# LM3S1626 register map
File version: 7944
Registers are 32-bit, read-write, no defined reset value unless marked. A register's access mark holds for its fields unless they carry their own. Offsets are from the block's base; [hi:lo] are bit positions; {n}, {i} and the like mark numbered series.

## QEI0 — Register map for QEI0 peripheral
Base 0x4002C000; register names take the prefix QEI0
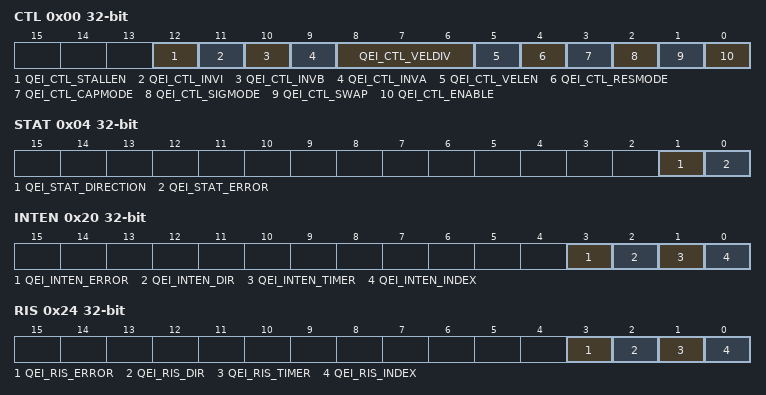
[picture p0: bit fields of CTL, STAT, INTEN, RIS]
0x00 CTL — QEI Control
  [12] QEI_CTL_STALLEN — Stall QEI
  [11] QEI_CTL_INVI — Invert Index Pulse
  [10] QEI_CTL_INVB — Invert PhB
  [9] QEI_CTL_INVA — Invert PhA
  [8:6] QEI_CTL_VELDIV — Predivide Velocity
    0=QEI clock /1; 1=QEI clock /2; 2=QEI clock /4; 3=QEI clock /8; 4=QEI clock /16; 5=QEI clock /32; 6=QEI clock /64; 7=QEI clock /128
  [5] QEI_CTL_VELEN — Capture Velocity
  [4] QEI_CTL_RESMODE — Reset Mode
  [3] QEI_CTL_CAPMODE — Capture Mode
  [2] QEI_CTL_SIGMODE — Signal Mode
  [1] QEI_CTL_SWAP — Swap Signals
  [0] QEI_CTL_ENABLE — Enable QEI
0x04 STAT — QEI Status
  [1] QEI_STAT_DIRECTION — Direction of Rotation
  [0] QEI_STAT_ERROR — Error Detected
0x08 POS — QEI Position
  [31:0] QEI_POS — Current Position Integrator Value
0x0C MAXPOS — QEI Maximum Position
  [31:0] QEI_MAXPOS — Maximum Position Integrator Value
0x10 LOAD — QEI Timer Load
  [31:0] QEI_LOAD — Velocity Timer Load Value
0x14 TIME — QEI Timer
  [31:0] QEI_TIME — Velocity Timer Current Value
0x18 COUNT — QEI Velocity Counter
  [31:0] QEI_COUNT — Velocity Pulse Count
0x1C SPEED — QEI Velocity
  [31:0] QEI_SPEED — Velocity
0x20 INTEN — QEI Interrupt Enable
  [3] QEI_INTEN_ERROR — Phase Error Interrupt Enable
  [2] QEI_INTEN_DIR — Direction Change Interrupt Enable
  [1] QEI_INTEN_TIMER — Timer Expires Interrupt Enable
  [0] QEI_INTEN_INDEX — Index Pulse Detected Interrupt Enable
0x24 RIS — QEI Raw Interrupt Status
  [3] QEI_RIS_ERROR — Phase Error Detected
  [2] QEI_RIS_DIR — Direction Change Detected
  [1] QEI_RIS_TIMER — Velocity Timer Expired
  [0] QEI_RIS_INDEX — Index Pulse Asserted
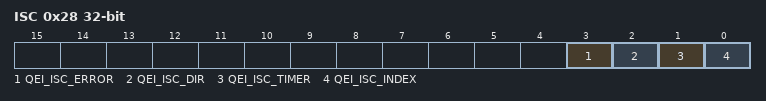
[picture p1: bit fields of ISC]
0x28 ISC — QEI Interrupt Status and Clear
  [3] QEI_ISC_ERROR — Phase Error Interrupt
  [2] QEI_ISC_DIR — Direction Change Interrupt
  [1] QEI_ISC_TIMER — Velocity Timer Expired Interrupt
  [0] QEI_ISC_INDEX — Index Pulse Interrupt

## FLASH_CTRL — Register map for FLASH_CTRL peripheral
Base 0x400FD000; register names take the prefix FLASH_CTRL
0x00 FMA — Flash Memory Address
  [16:0] FLASH_FMA_OFFSET — Address Offset
0x04 FMD — Flash Memory Data
  [31:0] FLASH_FMD_DATA — Data Value
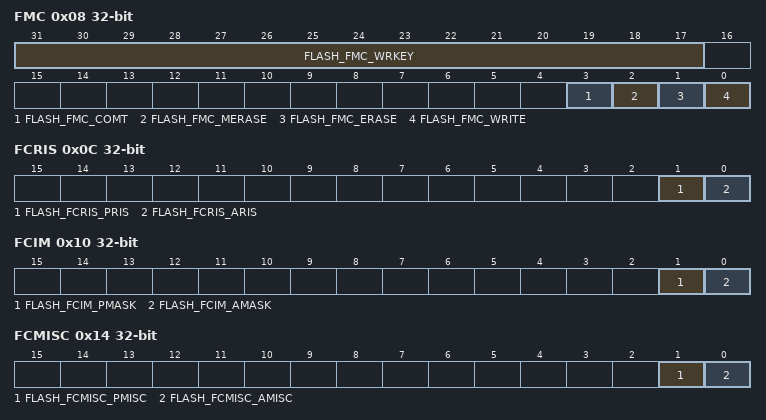
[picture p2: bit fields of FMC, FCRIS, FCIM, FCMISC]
0x08 FMC — Flash Memory Control
  [31:17] FLASH_FMC_WRKEY — FLASH write key
  [3] FLASH_FMC_COMT — Commit Register Value
  [2] FLASH_FMC_MERASE — Mass Erase Flash Memory
  [1] FLASH_FMC_ERASE — Erase a Page of Flash Memory
  [0] FLASH_FMC_WRITE — Write a Word into Flash Memory
0x0C FCRIS — Flash Controller Raw Interrupt Status
  [1] FLASH_FCRIS_PRIS — Programming Raw Interrupt Status
  [0] FLASH_FCRIS_ARIS — Access Raw Interrupt Status
0x10 FCIM — Flash Controller Interrupt Mask
  [1] FLASH_FCIM_PMASK — Programming Interrupt Mask
  [0] FLASH_FCIM_AMASK — Access Interrupt Mask
0x14 FCMISC — Flash Controller Masked Interrupt Status and Clear
  [1] FLASH_FCMISC_PMISC — Programming Masked Interrupt Status and Clear
  [0] FLASH_FCMISC_AMISC — Access Masked Interrupt Status and Clear
0x10F0 RMCTL — ROM Control
  [0] FLASH_RMCTL_BA — Boot Alias
0x1140 USECRL — USec Reload
  [7:0] FLASH_USECRL — Microsecond Reload Value
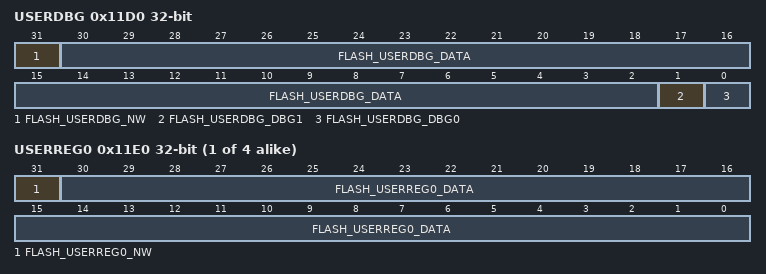
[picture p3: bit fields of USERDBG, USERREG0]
0x11D0 USERDBG (FLASH_ALT view) — User Debug
  [31] FLASH_USERDBG_NW — User Debug Not Written
  [30:2] FLASH_USERDBG_DATA — User Data
  [1] FLASH_USERDBG_DBG1 — Debug Control 1
  [0] FLASH_USERDBG_DBG0 — Debug Control 0
{0x11E0+4i} USERREG{i} (i=0..3) — User Register {i}
  [31] FLASH_USERREG{i}_NW — Not Written
  [30:0] FLASH_USERREG{i}_DATA — User Data
{0x1200+4i} FMPRE{i} (i=0..3) — Flash Memory Protection Read Enable {i}
{0x1400+4i} FMPPE{i} (i=0..3) — Flash Memory Protection Program Enable {i}

## UDMA — Register map for UDMA peripheral
Base 0x400FF000; register names take the prefix UDMA
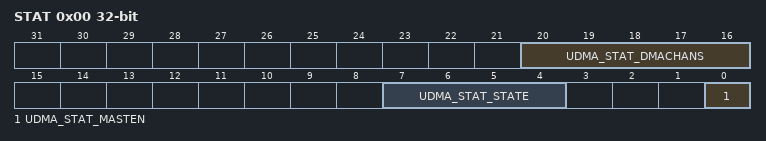
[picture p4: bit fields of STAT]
0x00 STAT — DMA Status
  [20:16] UDMA_STAT_DMACHANS — Available uDMA Channels Minus 1
  [7:4] UDMA_STAT_STATE — Control State Machine Status
    0=UDMA_STAT_STATE_IDLE (Idle); 1=UDMA_STAT_STATE_RD_CTRL (Reading channel controller data); 2=UDMA_STAT_STATE_RD_SRCENDP (Reading source end pointer); 3=UDMA_STAT_STATE_RD_DSTENDP (Reading destination end pointer); 4=UDMA_STAT_STATE_RD_SRCDAT (Reading source data); 5=UDMA_STAT_STATE_WR_DSTDAT (Writing destination data); 6=UDMA_STAT_STATE_WAIT (Waiting for uDMA request to clear); 7=UDMA_STAT_STATE_WR_CTRL (Writing channel controller data); 8=UDMA_STAT_STATE_STALL (Stalled); 9=UDMA_STAT_STATE_DONE (Done); 10=UDMA_STAT_STATE_UNDEF (Undefined)
  [0] UDMA_STAT_MASTEN — Master Enable Status
0x04 CFG wo — DMA Configuration
  [0] UDMA_CFG_MASTEN — Controller Master Enable
0x08 CTLBASE — DMA Channel Control Base Pointer
  [31:10] UDMA_CTLBASE_ADDR — Channel Control Base Address
0x0C ALTBASE — DMA Alternate Channel Control Base Pointer
  [31:0] UDMA_ALTBASE_ADDR — Alternate Channel Address Pointer
0x10 WAITSTAT — DMA Channel Wait-on-Request Status
  [31:0] UDMA_WAITSTAT_WAITREQ — Channel [n] Wait Status
0x14 SWREQ wo — DMA Channel Software Request
  [31:0] UDMA_SWREQ — Channel [n] Software Request
0x18 USEBURSTSET — DMA Channel Useburst Set
  [31:0] UDMA_USEBURSTSET_SET — Channel [n] Useburst Set
0x1C USEBURSTCLR wo — DMA Channel Useburst Clear
  [31:0] UDMA_USEBURSTCLR_CLR — Channel [n] Useburst Clear
0x20 REQMASKSET — DMA Channel Request Mask Set
  [31:0] UDMA_REQMASKSET_SET — Channel [n] Request Mask Set
0x24 REQMASKCLR wo — DMA Channel Request Mask Clear
  [31:0] UDMA_REQMASKCLR_CLR — Channel [n] Request Mask Clear
0x28 ENASET — DMA Channel Enable Set
  [31:0] UDMA_ENASET_SET — Channel [n] Enable Set
0x2C ENACLR wo — DMA Channel Enable Clear
  [31:0] UDMA_ENACLR_CLR — Clear Channel [n] Enable Clear
0x30 ALTSET — DMA Channel Primary Alternate Set
  [31:0] UDMA_ALTSET_SET — Channel [n] Alternate Set
0x34 ALTCLR wo — DMA Channel Primary Alternate Clear
  [31:0] UDMA_ALTCLR_CLR — Channel [n] Alternate Clear
0x38 PRIOSET — DMA Channel Priority Set
  [31:0] UDMA_PRIOSET_SET — Channel [n] Priority Set
0x3C PRIOCLR wo — DMA Channel Priority Clear
  [31:0] UDMA_PRIOCLR_CLR — Channel [n] Priority Clear
0x4C ERRCLR — DMA Bus Error Clear
  [0] UDMA_ERRCLR_ERRCLR — uDMA Bus Error Status
